# HT32F52342_52 register map
File version: 1.0
CPU: CM0+ r0p1, little endian, no MPU, no FPU, 4 interrupt priority bits
Registers are 32-bit, read-write, reset 0x0 unless marked. A register's access mark holds for its fields unless they carry their own. Offsets are from the block's base; [hi:lo] are bit positions; {n}, {i} and the like mark numbered series; 'fields as' and 'values as' point back to an identical list.

## AFIO
Base 0x40022000
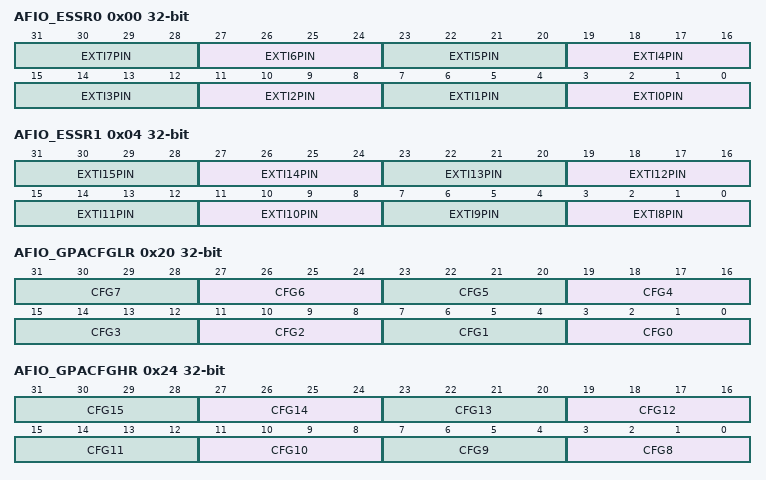
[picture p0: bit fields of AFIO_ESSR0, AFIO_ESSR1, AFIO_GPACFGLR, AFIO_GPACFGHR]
0x00 AFIO_ESSR0
  [4n+3:4n] EXTI{n}PIN (n=0..7)
0x04 AFIO_ESSR1
  [4n-29:4n-32] EXTI{n}PIN (n=8..15)
0x20 AFIO_GPACFGLR
  [4n+3:4n] CFG{n} (n=0..7)
0x24 AFIO_GPACFGHR
  [4n-29:4n-32] CFG{n} (n=8..15)
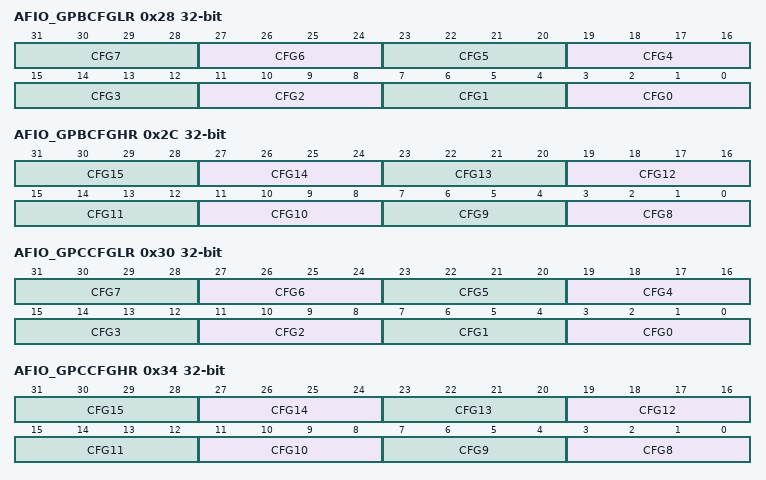
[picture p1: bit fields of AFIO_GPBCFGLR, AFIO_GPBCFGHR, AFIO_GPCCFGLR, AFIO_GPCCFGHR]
0x28 AFIO_GPBCFGLR
  [4n+3:4n] CFG{n} (n=0..7)
0x2C AFIO_GPBCFGHR
  [4n-29:4n-32] CFG{n} (n=8..15)
0x30 AFIO_GPCCFGLR
  [4n+3:4n] CFG{n} (n=0..7)
0x34 AFIO_GPCCFGHR
  [4n-29:4n-32] CFG{n} (n=8..15)
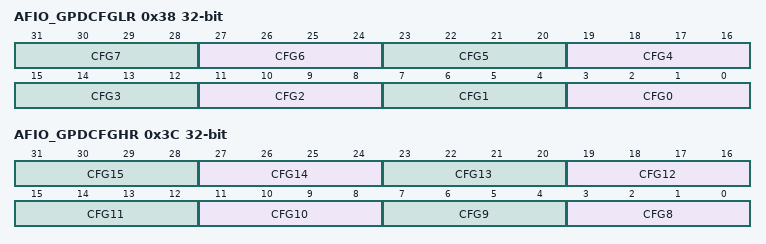
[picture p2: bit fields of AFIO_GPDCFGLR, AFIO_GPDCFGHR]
0x38 AFIO_GPDCFGLR
  [4n+3:4n] CFG{n} (n=0..7)
0x3C AFIO_GPDCFGHR
  [4n-29:4n-32] CFG{n} (n=8..15)

## EXTI
Base 0x40024000
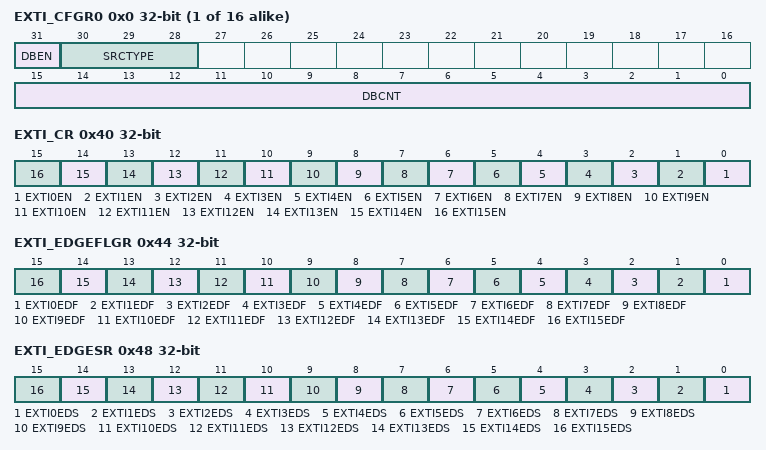
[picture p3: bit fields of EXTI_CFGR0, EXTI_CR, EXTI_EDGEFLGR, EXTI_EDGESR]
{0x0+4i} EXTI_CFGR{i} (i=0..15)
  [31] DBEN, [30:28] SRCTYPE, [15:0] DBCNT
0x40 EXTI_CR
  [n] EXTI{n}EN (n=0..15)
0x44 EXTI_EDGEFLGR
  [n] EXTI{n}EDF (n=0..15)
0x48 EXTI_EDGESR
  [n] EXTI{n}EDS (n=0..15)
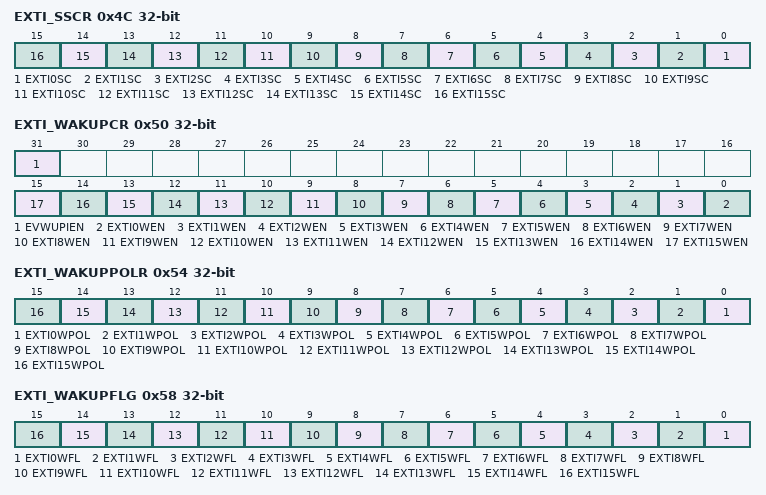
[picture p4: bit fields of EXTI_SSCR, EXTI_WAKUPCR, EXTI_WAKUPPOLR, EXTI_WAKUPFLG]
0x4C EXTI_SSCR
  [n] EXTI{n}SC (n=0..15)
0x50 EXTI_WAKUPCR
  [31] EVWUPIEN, [n] EXTI{n}WEN (n=0..15)
0x54 EXTI_WAKUPPOLR
  [n] EXTI{n}WPOL (n=0..15)
0x58 EXTI_WAKUPFLG
  [n] EXTI{n}WFL (n=0..15)

## ADC
Base 0x40010000
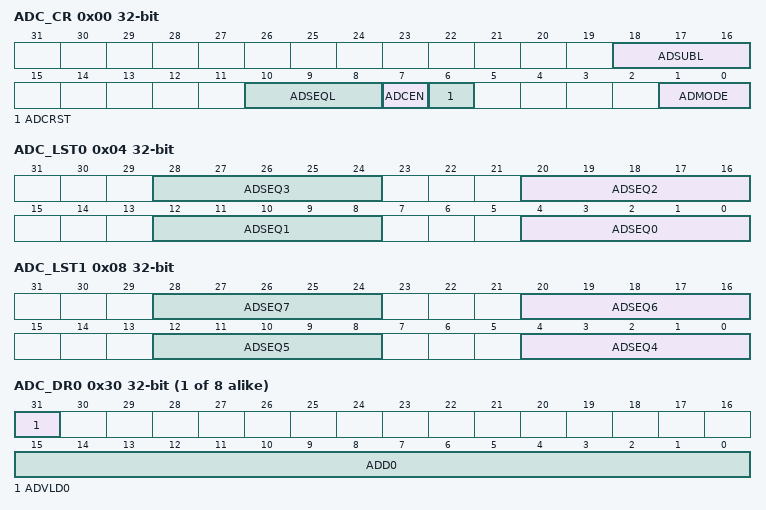
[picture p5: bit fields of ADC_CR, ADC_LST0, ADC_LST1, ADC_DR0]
0x00 ADC_CR
  [18:16] ADSUBL, [10:8] ADSEQL, [7] ADCEN, [6] ADCRST, [1:0] ADMODE
0x04 ADC_LST0
  [8n+4:8n] ADSEQ{n} (n=0..3)
0x08 ADC_LST1
  [8n-28:8n-32] ADSEQ{n} (n=4..7)
0x20 ADC_STR
  [7:0] ADST
{0x30+4i} ADC_DR{i} (i=0..7)
  [31] ADVLD{i}, [15:0] ADD{i}
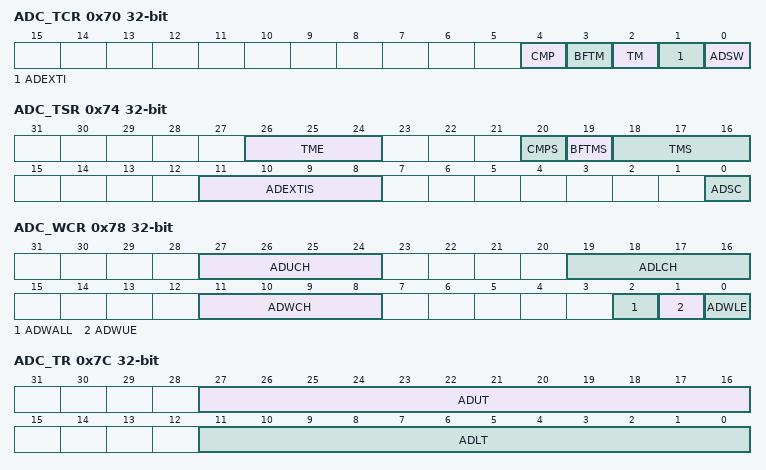
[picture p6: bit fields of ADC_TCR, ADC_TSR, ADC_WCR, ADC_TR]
0x70 ADC_TCR
  [4] CMP, [3] BFTM, [2] TM, [1] ADEXTI, [0] ADSW
0x74 ADC_TSR
  [26:24] TME, [20] CMPS, [19] BFTMS, [18:16] TMS, [11:8] ADEXTIS, [0] ADSC
0x78 ADC_WCR
  [27:24] ADUCH, [19:16] ADLCH, [11:8] ADWCH, [2] ADWALL, [1] ADWUE, [0] ADWLE
0x7C ADC_TR
  [27:16] ADUT, [11:0] ADLT
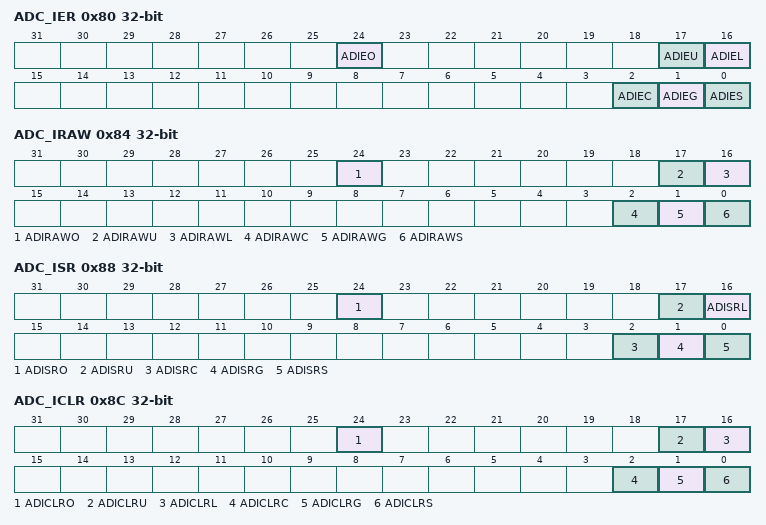
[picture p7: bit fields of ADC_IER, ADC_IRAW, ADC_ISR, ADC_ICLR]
0x80 ADC_IER — ADC_IMR
  [24] ADIEO, [17] ADIEU, [16] ADIEL, [2] ADIEC, [1] ADIEG, [0] ADIES
0x84 ADC_IRAW
  [24] ADIRAWO, [17] ADIRAWU, [16] ADIRAWL, [2] ADIRAWC, [1] ADIRAWG, [0] ADIRAWS
0x88 ADC_ISR
  [24] ADISRO, [17] ADISRU, [16] ADISRL, [2] ADISRC, [1] ADISRG, [0] ADISRS
0x8C ADC_ICLR
  [24] ADICLRO, [17] ADICLRU, [16] ADICLRL, [2] ADICLRC, [1] ADICLRG, [0] ADICLRS
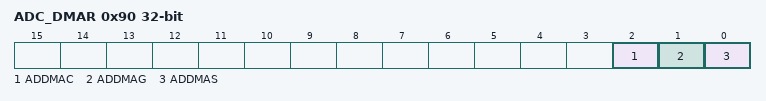
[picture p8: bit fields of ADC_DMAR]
0x90 ADC_DMAR
  [2] ADDMAC, [1] ADDMAG, [0] ADDMAS

## CMP
Base 0x40058000
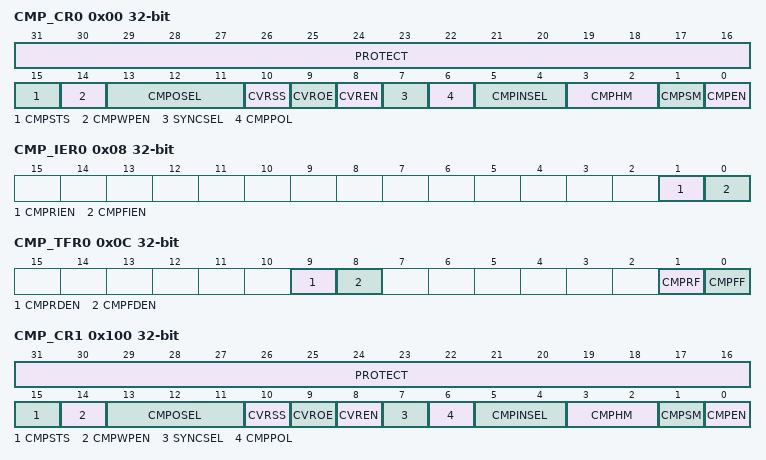
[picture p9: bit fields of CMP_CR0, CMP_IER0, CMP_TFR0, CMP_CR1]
0x00 CMP_CR0
  [31:16] PROTECT, [15] CMPSTS, [14] CMPWPEN, [13:11] CMPOSEL, [10] CVRSS, [9] CVROE, [8] CVREN, [7] SYNCSEL, [6] CMPPOL, [5:4] CMPINSEL, [3:2] CMPHM, [1] CMPSM, [0] CMPEN
0x04 CMP_VALR0
  [5:0] CVRVAL
0x08 CMP_IER0
  [1] CMPRIEN, [0] CMPFIEN
0x0C CMP_TFR0
  [9] CMPRDEN, [8] CMPFDEN, [1] CMPRF, [0] CMPFF
0x100 CMP_CR1
  fields as CMP_CR0
0x104 CMP_VALR1
  [5:0] CVRVAL
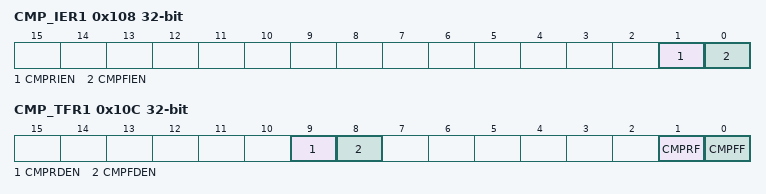
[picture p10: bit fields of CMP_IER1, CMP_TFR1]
0x108 CMP_IER1
  [1] CMPRIEN, [0] CMPFIEN
0x10C CMP_TFR1
  [9] CMPRDEN — CMPRF
  [8] CMPFDEN
  [1] CMPRF
  [0] CMPFF

## MCTM0
Base 0x4002C000
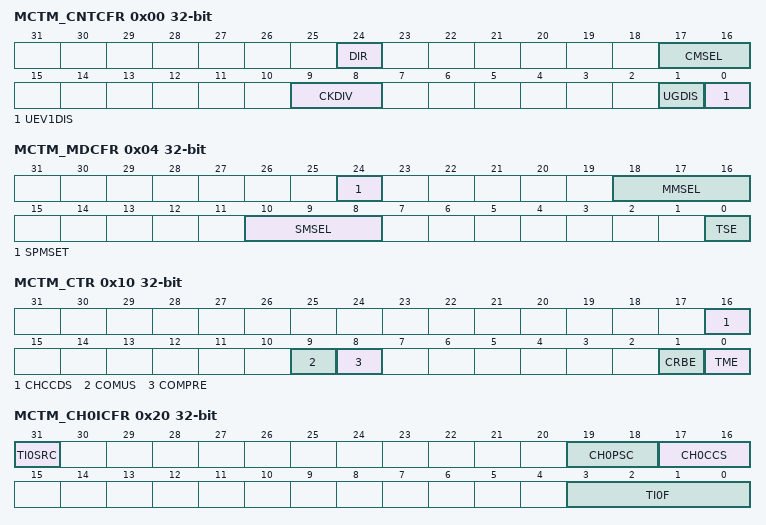
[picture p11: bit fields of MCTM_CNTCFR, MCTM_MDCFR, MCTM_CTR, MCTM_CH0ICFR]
0x00 MCTM_CNTCFR
  [24] DIR, [17:16] CMSEL, [9:8] CKDIV, [1] UGDIS, [0] UEV1DIS
0x04 MCTM_MDCFR
  [24] SPMSET, [18:16] MMSEL, [10:8] SMSEL, [0] TSE
0x08 MCTM_TRCFR
  [3:0] TRSEL
0x10 MCTM_CTR
  [16] CHCCDS, [9] COMUS, [8] COMPRE, [1] CRBE, [0] TME
0x20 MCTM_CH0ICFR
  [31] TI0SRC, [19:18] CH0PSC, [17:16] CH0CCS, [3:0] TI0F
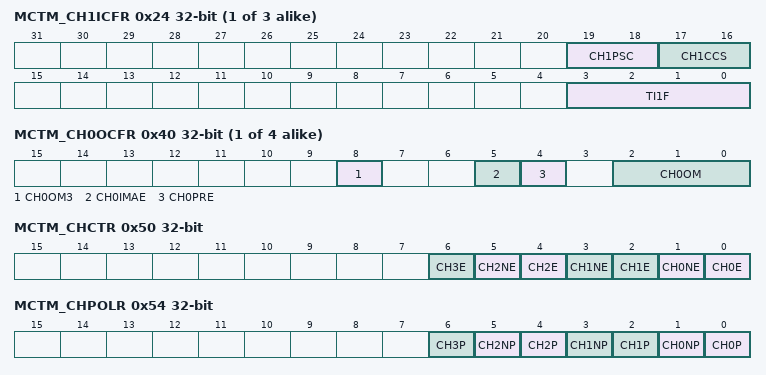
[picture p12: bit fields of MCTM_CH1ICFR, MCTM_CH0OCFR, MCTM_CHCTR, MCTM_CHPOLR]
{0x20+4i} MCTM_CH{i}ICFR (i=1..3)
  [19:18] CH{i}PSC, [17:16] CH{i}CCS, [3:0] TI{i}F
{0x40+4i} MCTM_CH{i}OCFR (i=0..3)
  [8] CH{i}OM3, [5] CH{i}IMAE, [4] CH{i}PRE, [2:0] CH{i}OM
0x50 MCTM_CHCTR
  [2n] CH{n}E (n=0..3), [5] CH2NE, [3] CH1NE, [1] CH0NE
0x54 MCTM_CHPOLR
  [2n] CH{n}P (n=0..3), [5] CH2NP, [3] CH1NP, [1] CH0NP
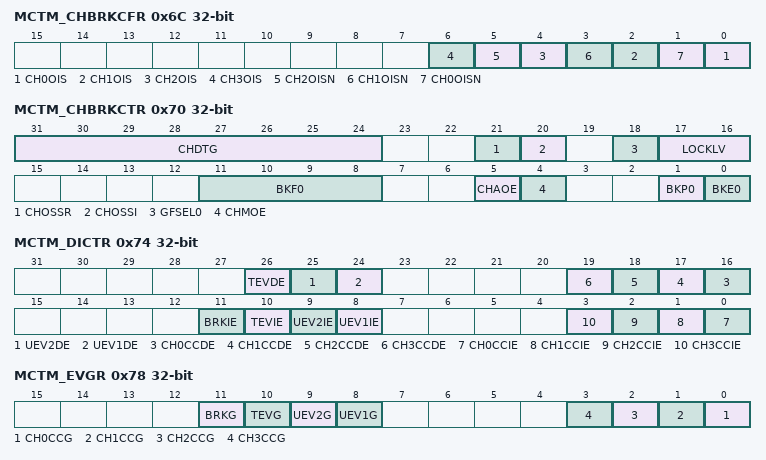
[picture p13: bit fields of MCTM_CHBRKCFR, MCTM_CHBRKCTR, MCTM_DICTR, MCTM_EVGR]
0x6C MCTM_CHBRKCFR
  [2n] CH{n}OIS (n=0..3), [5] CH2OISN, [3] CH1OISN, [1] CH0OISN
0x70 MCTM_CHBRKCTR
  [31:24] CHDTG, [21] CHOSSR, [20] CHOSSI, [18] GFSEL0, [17:16] LOCKLV, [11:8] BKF0, [5] CHAOE, [4] CHMOE, [1] BKP0, [0] BKE0
0x74 MCTM_DICTR
  [26] TEVDE, [25] UEV2DE, [24] UEV1DE, [n+16] CH{n}CCDE (n=0..3), [11] BRKIE, [10] TEVIE, [9] UEV2IE, [8] UEV1IE, [n] CH{n}CCIE (n=0..3)
0x78 MCTM_EVGR
  [11] BRKG, [10] TEVG, [9] UEV2G, [8] UEV1G, [n] CH{n}CCG (n=0..3)
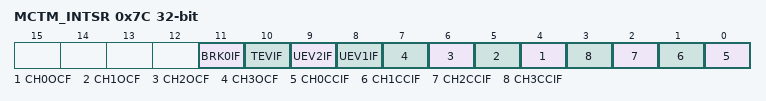
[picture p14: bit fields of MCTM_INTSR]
0x7C MCTM_INTSR
  [11] BRK0IF, [10] TEVIF, [9] UEV2IF, [8] UEV1IF, [n+4] CH{n}OCF (n=0..3), [n] CH{n}CCIF (n=0..3)
0x80 MCTM_CNTR
  [15:0] CNTV
0x84 MCTM_PSCR
  [15:0] PSCV
0x88 MCTM_CRR
  [15:0] CRV
0x8C MCTM_REPR
  [7:0] REPV
{0x90+4i} MCTM_CH{i}CCR (i=0..3)
  [15:0] CH{i}CCV
{0xA0+4i} MCTM_CH{i}ACR (i=0..3)
  [15:0] CH{i}ACV

## Notices in the file
Copyright (C) 2010 ARM Limited. All rights reserved.
ARM Limited (ARM) is supplying this SVD description for use with Cortex-M3
processor based microcontrollers.  This file and or content can be freely
distributed within development tools that are supporting such ARM based
processors.
THIS SOFTWARE IS PROVIDED "AS IS".  NO WARRANTIES, WHETHER EXPRESS, IMPLIED
OR STATUTORY, INCLUDING, BUT NOT LIMITED TO, IMPLIED WARRANTIES OF
MERCHANTABILITY AND FITNESS FOR A PARTICULAR PURPOSE APPLY TO THIS SOFTWARE.
ARM SHALL NOT, IN ANY CIRCUMSTANCES, BE LIABLE FOR SPECIAL, INCIDENTAL, OR
CONSEQUENTIAL DAMAGES, FOR ANY REASON WHATSOEVER.
